AUTOSAR XML (schema 4-2-2)
package /Components
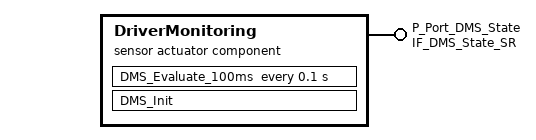
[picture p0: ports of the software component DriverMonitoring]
  sensor actuator sw component type DriverMonitoring
    provide port P_Port_DMS_State: provided-interface=IF_DMS_State_SR
    behavior DriverMonitoring_InternalBehavior
      init event DMS_Init_Event: start-on-event=DMS_Init
      timing event DMS_Tick: start-on-event=DMS_Evaluate_100ms, period=0.1
      runnable DMS_Init
        parameter access PA_Read_Drowsiness_Threshold: accessed-parameter=P_Port_DMS_State.Drowsiness_Level
        parameter access PA_Read_Attention_Threshold: accessed-parameter=P_Port_DMS_State.Driver_Attention
      runnable DMS_Evaluate_100ms: minimum-start-interval=0.1
        data-send-points:
          4 x access:
            VA_Send_Driver_Attention: accessed-variable=P_Port_DMS_State.Driver_Attention
            VA_Send_Drowsiness_Level: accessed-variable=P_Port_DMS_State.Drowsiness_Level
            VA_Send_Eyes_Off_Road: accessed-variable=P_Port_DMS_State.Eyes_Off_Road
            VA_Send_Timestamp: accessed-variable=P_Port_DMS_State.Timestamp
